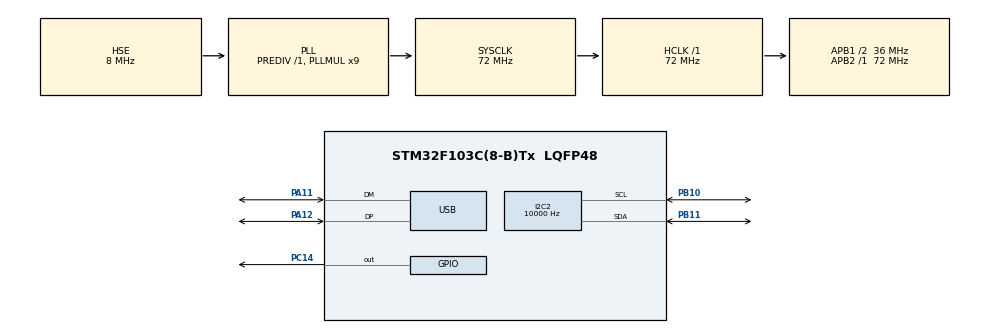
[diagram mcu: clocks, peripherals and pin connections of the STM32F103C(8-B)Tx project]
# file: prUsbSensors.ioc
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I2C2.ClockSpeed=10000
Mcu.Family=STM32F1
Mcu.Name=STM32F103C(8-B)Tx
Mcu.Package=LQFP48
NVIC.PriorityGroup=NVIC_PRIORITYGROUP_4
NVIC.TIM4_IRQn=true\:0\:0\:false\:false\:true\:true\:true
NVIC.USB_LP_CAN1_RX0_IRQn=true\:10\:0\:true\:false\:true\:false\:true
PA11.Mode=Device
PA11.Signal=USB_DM
PA12.Mode=Device
PA12.Signal=USB_DP
PA13.Mode=Serial_Wire
PA13.Signal=SYS_JTMS-SWDIO
PA14.Mode=Serial_Wire
PA14.Signal=SYS_JTCK-SWCLK
PB10.Mode=I2C
PB10.Signal=I2C2_SCL
PB11.Mode=I2C
PB11.Signal=I2C2_SDA
PC14-OSC32_IN.GPIO_PuPd=GPIO_NOPULL
PC14-OSC32_IN.PinState=GPIO_PIN_RESET
PC14-OSC32_IN.Signal=GPIO_Output
PD0-OSC_IN.Mode=HSE-External-Oscillator
PD0-OSC_IN.Signal=RCC_OSC_IN
PD1-OSC_OUT.Mode=HSE-External-Oscillator
PD1-OSC_OUT.Signal=RCC_OSC_OUT
ProjectManager.HeapSize=0x800
ProjectManager.StackSize=0x800
ProjectManager.TargetToolchain=STM32CubeIDE
RCC.AHBFreq_Value=72000000
RCC.APB1CLKDivider=RCC_HCLK_DIV2
RCC.APB1Freq_Value=36000000
RCC.APB1TimFreq_Value=72000000
RCC.APB2Freq_Value=72000000
RCC.APB2TimFreq_Value=72000000
RCC.HCLKFreq_Value=72000000
RCC.PLLMUL=RCC_PLL_MUL9
RCC.SYSCLKFreq_VALUE=72000000
RCC.SYSCLKSource=RCC_SYSCLKSOURCE_PLLCLK
RCC.USBFreq_Value=48000000
RCC.USBPrescaler=RCC_USBCLKSOURCE_PLL_DIV1_5
TIM4.Period=3199
TIM4.Prescaler=449
TIM4.TIM_MasterOutputTrigger=TIM_TRGO_UPDATE
USB_DEVICE.APP_RX_DATA_SIZE=20
USB_DEVICE.APP_TX_DATA_SIZE=20
USB_DEVICE.CLASS_NAME_FS=CDC
USB_DEVICE.MANUFACTURER_STRING=SKBE Energia
USB_DEVICE.PRODUCT_STRING_CDC_FS=STM32 Virtual ComPort
USB_DEVICE.VirtualMode=Cdc
USB_DEVICE.VirtualModeFS=Cdc_FS
VP_RTC_VS_RTC_Activate.Mode=RTC_Enabled
VP_RTC_VS_RTC_Calendar.Mode=RTC_Calendar
VP_TIM4_VS_ClockSourceINT.Mode=Internal
VP_TIM4_VS_OPM.Mode=OPM_bit
VP_USB_DEVICE_VS_USB_DEVICE_CDC_FS.Mode=CDC_FS
board=custom

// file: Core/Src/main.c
/* USER CODE BEGIN Header */
/**
  ******************************************************************************
  * @file           : main.c
  * @brief          : Main program body
  ******************************************************************************
  * @attention
  *
  * <h2><center>&copy; Copyright (c) 2021 STMicroelectronics.
  * All rights reserved.</center></h2>
  *
  * This software component is licensed by ST under BSD 3-Clause license,
  * the "License"; You may not use this file except in compliance with the
  * License. You may obtain a copy of the License at:
  *                        opensource.org/licenses/BSD-3-Clause
  *
  ******************************************************************************
  */
/* USER CODE END Header */

#include "main.h"
#include "i2c.h"
#include "rtc.h"
#include "tim.h"
#include "usb_device.h"
#include "gpio.h"

/* USER CODE BEGIN Includes */

#include "common.h"

/* USER CODE END Includes */

/* USER CODE BEGIN PV */

//uint8_t testBufRx [] = { 0x1F, 0x00, 0x01, 0x24, 0xFE, 0xC3, 0xF3, 0x2F, 0x55 } ;	// Команда FE (Проверка адреса и SN)
//uint8_t testBufRx [] = { 0x1F, 0x00, 0x01, 0x24, 0x01, 0x33, 0x44, 0x22, 0x7B, 0xEB, 0x2F, 0x55 } ;	// Команда 01 (Запись адреса и SN)
//uint8_t testBufRx [] = { 0x1F, 0x00, 0x01, 0x24, 0x00, 0x33, 0x44, 0x68, 0x0F, 0x2F, 0x55 } ;	// Команда 00 (Запись SN)
//uint8_t testBufRx [] = { 0x1F, 0x22, 0x01, 0x24, 0xFD, 0x3D, 0x05, 0x0C, 0x05, 0x1F, 0x1F, 0x1F, 0x1F, 0x42, 0x7F, 0x2F, 0x55 } ;	// Команда FD (Запись текущего времени) Специально время указано как 31 мин, 31 сек
//uint8_t testBufRx [] = { 0x1F, 0x22, 0x01, 0x24, 0x50, 0xC1, 0x7D, 0x2F, 0x55 } ;	// Команда FE (Проверка адреса и SN)

/* USER CODE END PV */

void SystemClock_Config(void);

int main(void)
{

  /* MCU Configuration--------------------------------------------------------*/

  /* Reset of all peripherals, Initializes the Flash interface and the Systick. */
  HAL_Init();

  /* Configure the system clock */
  SystemClock_Config();

  /* Initialize all configured peripherals */
  MX_GPIO_Init();
  MX_I2C2_Init();
  MX_RTC_Init();
  MX_USB_DEVICE_Init();
  MX_TIM4_Init();
  /* USER CODE BEGIN 2 */

  stState = enReady ;			// Инициализируе рабочее состояние
  HAL_TIM_Base_Start_IT(&htim4);
  HAL_Delay(100) ;

  /* USER CODE END 2 */

  /* Infinite loop */
  /* USER CODE BEGIN WHILE */

  bool isXXX = true ;

  while (1)
  {
	  	  	  	  	  // Тупо опрашиваем датчик 2 раза в секунду и при ошибке мигаем светодиодом с частотой около 1 гц.
	  if (getSHT () == HAL_OK) HAL_GPIO_WritePin (defBlinkLedPort, defBlinkLedPin, GPIO_PIN_SET);
	    else HAL_GPIO_TogglePin(defBlinkLedPort, defBlinkLedPin) ;
	  HAL_Delay(500) ;

//	    for (uint8_t i = 0; i < sizeof (testBufRx) && isXXX ; ++i)
//	  	  receiveByte (testBufRx [i]) ;
//	    isXXX = false ;

    /* USER CODE END WHILE */

  }
}

void SystemClock_Config(void)
{
  RCC_OscInitTypeDef RCC_OscInitStruct = {0};
  RCC_ClkInitTypeDef RCC_ClkInitStruct = {0};
  RCC_PeriphCLKInitTypeDef PeriphClkInit = {0};

  /** Initializes the CPU, AHB and APB busses clocks
  */
  RCC_OscInitStruct.OscillatorType = RCC_OSCILLATORTYPE_LSI|RCC_OSCILLATORTYPE_HSE;
  RCC_OscInitStruct.HSEState = RCC_HSE_ON;
  RCC_OscInitStruct.HSEPredivValue = RCC_HSE_PREDIV_DIV1;
  RCC_OscInitStruct.HSIState = RCC_HSI_ON;
  RCC_OscInitStruct.LSIState = RCC_LSI_ON;
  RCC_OscInitStruct.PLL.PLLState = RCC_PLL_ON;
  RCC_OscInitStruct.PLL.PLLSource = RCC_PLLSOURCE_HSE;
  RCC_OscInitStruct.PLL.PLLMUL = RCC_PLL_MUL9;
  if (HAL_RCC_OscConfig(&RCC_OscInitStruct) != HAL_OK)
  {
    Error_Handler();
  }
  /** Initializes the CPU, AHB and APB busses clocks
  */
  RCC_ClkInitStruct.ClockType = RCC_CLOCKTYPE_HCLK|RCC_CLOCKTYPE_SYSCLK
                              |RCC_CLOCKTYPE_PCLK1|RCC_CLOCKTYPE_PCLK2;
  RCC_ClkInitStruct.SYSCLKSource = RCC_SYSCLKSOURCE_PLLCLK;
  RCC_ClkInitStruct.AHBCLKDivider = RCC_SYSCLK_DIV1;
  RCC_ClkInitStruct.APB1CLKDivider = RCC_HCLK_DIV2;
  RCC_ClkInitStruct.APB2CLKDivider = RCC_HCLK_DIV1;

  if (HAL_RCC_ClockConfig(&RCC_ClkInitStruct, FLASH_LATENCY_2) != HAL_OK)
  {
    Error_Handler();
  }
  PeriphClkInit.PeriphClockSelection = RCC_PERIPHCLK_RTC|RCC_PERIPHCLK_USB;
  PeriphClkInit.RTCClockSelection = RCC_RTCCLKSOURCE_LSI;
  PeriphClkInit.UsbClockSelection = RCC_USBCLKSOURCE_PLL_DIV1_5;
  if (HAL_RCCEx_PeriphCLKConfig(&PeriphClkInit) != HAL_OK)
  {
    Error_Handler();
  }
}

void Error_Handler(void)
{
}

/************************ (C) COPYRIGHT STMicroelectronics *****END OF FILE****/
